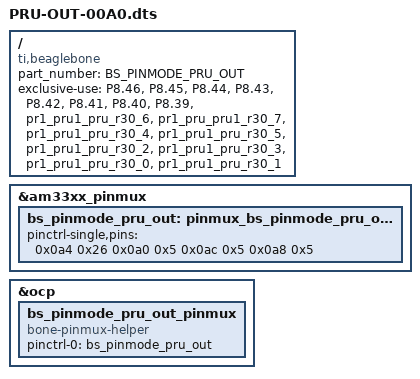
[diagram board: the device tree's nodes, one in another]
/dts-v1/;
/plugin/;

/{
    compatible = "ti,beaglebone", "ti,beaglebone-black";
    part_number = "BS_PINMODE_PRU_OUT";

    exclusive-use =
    "P8.46",
    "P8.45",
    "P8.44",
    "P8.43",
    "P8.42",
    "P8.41",
    "P8.40",
    "P8.39",
    "pr1_pru1_pru_r30_6",
    "pr1_pru_pru1_r30_7",
    "pr1_pru1_pru_r30_4",
    "pr1_pru1_pru_r30_5",
    "pr1_pru1_pru_r30_2",
    "pr1_pru1_pru_r30_3",
    "pr1_pru1_pru_r30_0",
    "pr1_pru1_pru_r30_1";

    fragment@0 {
    target = <&am33xx_pinmux>;
    __overlay__ {
        bs_pinmode_pru_out: pinmux_bs_pinmode_pru_out {
            pinctrl-single,pins = <
		0x0a4 0x26 
		0x0a0 0x5 
		0x0ac 0x5 
		0x0a8 0x5>;
        };
    };
};

    fragment@1 {
        target = <&ocp>;
        __overlay__ {
            bs_pinmode_pru_out_pinmux {
                compatible = "bone-pinmux-helper";
                status = "okay";
                pinctrl-names = "default";
                pinctrl-0 = <&bs_pinmode_pru_out>;
            };
        };
    };
};
